AUTOSAR XML (schema 4-3-0)
package /ComponentTypes
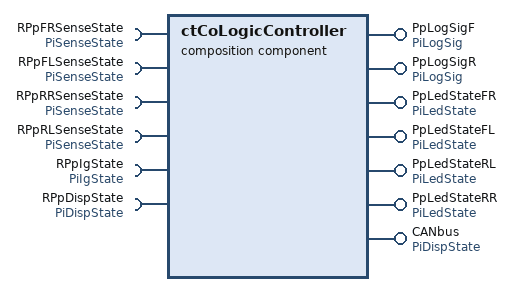
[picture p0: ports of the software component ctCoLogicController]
  composition sw component type ctCoLogicController
    6 x require port:
      RPpFRSenseState: nonqueued-receiver-com-spec{data-element=DePiSenseState, filter=data-filter-type=ALWAYS, init-value=0}, required-interface=PiSenseState
      RPpFLSenseState: nonqueued-receiver-com-spec{data-element=DePiSenseState, filter=data-filter-type=ALWAYS, init-value=0}, required-interface=PiSenseState
      RPpRRSenseState: nonqueued-receiver-com-spec{data-element=DePiSenseState, filter=data-filter-type=ALWAYS, init-value=0}, required-interface=PiSenseState
      RPpRLSenseState: nonqueued-receiver-com-spec{data-element=DePiSenseState, filter=data-filter-type=ALWAYS, init-value=0}, required-interface=PiSenseState
      RPpIgState: nonqueued-receiver-com-spec{data-element=DePiIgState, filter=data-filter-type=ALWAYS, init-value=0}, required-interface=PiIgState
      RPpDispState: nonqueued-receiver-com-spec{data-element=DePiDispState, filter=data-filter-type=ALWAYS, init-value=0}, required-interface=PiDispState
    7 x provide port:
      PpLogSigF: nonqueued-sender-com-spec=DePiLedState, provided-interface=PiLogSig
      PpLogSigR: nonqueued-sender-com-spec=DePiLedState, provided-interface=PiLogSig
      PpLedStateFR: nonqueued-sender-com-spec{data-element=DePiLedState, init-value=0}, provided-interface=PiLedState
      PpLedStateFL: nonqueued-sender-com-spec=DePiLedState, provided-interface=PiLedState
      PpLedStateRL: nonqueued-sender-com-spec{data-element=DePiLedState, init-value=0}, provided-interface=PiLedState
      PpLedStateRR: nonqueued-sender-com-spec=DePiLedState, provided-interface=PiLedState
      CANbus: nonqueued-sender-com-spec=DePiDispState, provided-interface=PiDispState
    component CtApSwitchDecoder: type=CtApSwitchDecoder
    component CtApBlinker: type=CtApBlinker
    connect CtApSwitchDecoder.PpLogSig -> CtApBlinker.PpLogSwitchState
